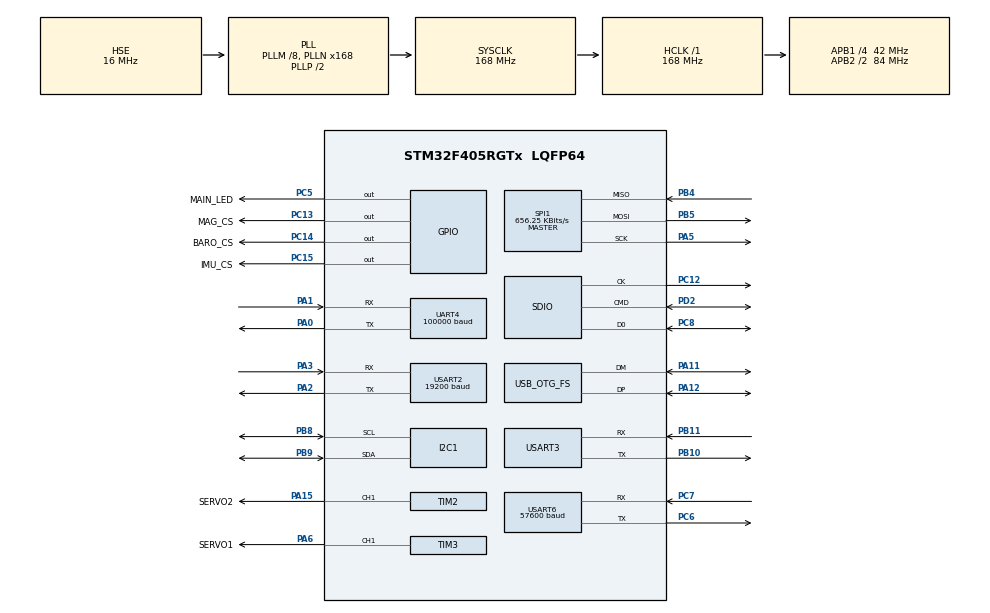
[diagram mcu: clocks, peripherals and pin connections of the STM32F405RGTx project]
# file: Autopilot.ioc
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Dma.Request0=SDIO_RX
Dma.Request1=SDIO_TX
Dma.Request2=USART3_RX
Dma.Request3=UART4_RX
Dma.Request4=USART6_RX
Dma.Request5=USART2_RX
Dma.SDIO_RX.0.Direction=DMA_PERIPH_TO_MEMORY
Dma.SDIO_RX.0.FIFOMode=DMA_FIFOMODE_ENABLE
Dma.SDIO_RX.0.FIFOThreshold=DMA_FIFO_THRESHOLD_FULL
Dma.SDIO_RX.0.Instance=DMA2_Stream3
Dma.SDIO_RX.0.MemBurst=DMA_MBURST_INC4
Dma.SDIO_RX.0.MemDataAlignment=DMA_MDATAALIGN_WORD
Dma.SDIO_RX.0.MemInc=DMA_MINC_ENABLE
Dma.SDIO_RX.0.Mode=DMA_PFCTRL
Dma.SDIO_RX.0.PeriphBurst=DMA_PBURST_INC4
Dma.SDIO_RX.0.PeriphDataAlignment=DMA_PDATAALIGN_WORD
Dma.SDIO_RX.0.PeriphInc=DMA_PINC_DISABLE
Dma.SDIO_RX.0.Priority=DMA_PRIORITY_LOW
Dma.SDIO_TX.1.Direction=DMA_MEMORY_TO_PERIPH
Dma.SDIO_TX.1.FIFOMode=DMA_FIFOMODE_ENABLE
Dma.SDIO_TX.1.FIFOThreshold=DMA_FIFO_THRESHOLD_FULL
Dma.SDIO_TX.1.Instance=DMA2_Stream6
Dma.SDIO_TX.1.MemBurst=DMA_MBURST_INC4
Dma.SDIO_TX.1.MemDataAlignment=DMA_MDATAALIGN_WORD
Dma.SDIO_TX.1.MemInc=DMA_MINC_ENABLE
Dma.SDIO_TX.1.Mode=DMA_PFCTRL
Dma.SDIO_TX.1.PeriphBurst=DMA_PBURST_INC4
Dma.SDIO_TX.1.PeriphDataAlignment=DMA_PDATAALIGN_WORD
Dma.SDIO_TX.1.PeriphInc=DMA_PINC_DISABLE
Dma.SDIO_TX.1.Priority=DMA_PRIORITY_LOW
Dma.UART4_RX.3.Direction=DMA_PERIPH_TO_MEMORY
Dma.UART4_RX.3.FIFOMode=DMA_FIFOMODE_DISABLE
Dma.UART4_RX.3.Instance=DMA1_Stream2
Dma.UART4_RX.3.MemDataAlignment=DMA_MDATAALIGN_BYTE
Dma.UART4_RX.3.MemInc=DMA_MINC_ENABLE
Dma.UART4_RX.3.Mode=DMA_NORMAL
Dma.UART4_RX.3.PeriphDataAlignment=DMA_PDATAALIGN_BYTE
Dma.UART4_RX.3.PeriphInc=DMA_PINC_DISABLE
Dma.UART4_RX.3.Priority=DMA_PRIORITY_LOW
Dma.USART2_RX.5.Direction=DMA_PERIPH_TO_MEMORY
Dma.USART2_RX.5.FIFOMode=DMA_FIFOMODE_DISABLE
Dma.USART2_RX.5.Instance=DMA1_Stream5
Dma.USART2_RX.5.MemDataAlignment=DMA_MDATAALIGN_BYTE
Dma.USART2_RX.5.MemInc=DMA_MINC_ENABLE
Dma.USART2_RX.5.Mode=DMA_NORMAL
Dma.USART2_RX.5.PeriphDataAlignment=DMA_PDATAALIGN_BYTE
Dma.USART2_RX.5.PeriphInc=DMA_PINC_DISABLE
Dma.USART2_RX.5.Priority=DMA_PRIORITY_LOW
Dma.USART3_RX.2.Direction=DMA_PERIPH_TO_MEMORY
Dma.USART3_RX.2.FIFOMode=DMA_FIFOMODE_DISABLE
Dma.USART3_RX.2.Instance=DMA1_Stream1
Dma.USART3_RX.2.MemDataAlignment=DMA_MDATAALIGN_BYTE
Dma.USART3_RX.2.MemInc=DMA_MINC_ENABLE
Dma.USART3_RX.2.Mode=DMA_NORMAL
Dma.USART3_RX.2.PeriphDataAlignment=DMA_PDATAALIGN_BYTE
Dma.USART3_RX.2.PeriphInc=DMA_PINC_DISABLE
Dma.USART3_RX.2.Priority=DMA_PRIORITY_LOW
Dma.USART6_RX.4.Direction=DMA_PERIPH_TO_MEMORY
Dma.USART6_RX.4.FIFOMode=DMA_FIFOMODE_DISABLE
Dma.USART6_RX.4.Instance=DMA2_Stream1
Dma.USART6_RX.4.MemDataAlignment=DMA_MDATAALIGN_BYTE
Dma.USART6_RX.4.MemInc=DMA_MINC_ENABLE
Dma.USART6_RX.4.Mode=DMA_NORMAL
Dma.USART6_RX.4.PeriphDataAlignment=DMA_PDATAALIGN_BYTE
Dma.USART6_RX.4.PeriphInc=DMA_PINC_DISABLE
Dma.USART6_RX.4.Priority=DMA_PRIORITY_LOW
FATFS.USE_DMA_CODE_SD=1
FATFS._MAX_SS=4096
FATFS._USE_LFN=1
I2C1.I2C_Mode=I2C_Fast
Mcu.Family=STM32F4
Mcu.Name=STM32F405RGTx
Mcu.Package=LQFP64
NVIC.DMA1_Stream1_IRQn=true\:0\:0\:false\:false\:true\:false\:true\:true
NVIC.DMA1_Stream2_IRQn=true\:0\:0\:false\:false\:true\:false\:true\:true
NVIC.DMA1_Stream5_IRQn=true\:0\:0\:false\:false\:true\:false\:true\:true
NVIC.DMA2_Stream1_IRQn=true\:0\:0\:false\:false\:true\:false\:true\:true
NVIC.DMA2_Stream3_IRQn=true\:0\:0\:false\:false\:true\:false\:true\:true
NVIC.DMA2_Stream6_IRQn=true\:0\:0\:false\:false\:true\:false\:true\:true
NVIC.OTG_FS_IRQn=true\:0\:0\:false\:false\:true\:false\:true\:true
NVIC.PriorityGroup=NVIC_PRIORITYGROUP_4
NVIC.SDIO_IRQn=true\:0\:0\:false\:false\:true\:true\:true\:true
NVIC.TIM6_DAC_IRQn=true\:15\:0\:true\:false\:true\:true\:true\:true
NVIC.TIM7_IRQn=true\:14\:0\:true\:false\:true\:true\:true\:true
PA0-WKUP.Mode=Asynchronous
PA0-WKUP.Signal=UART4_TX
PA1.Mode=Asynchronous
PA1.Signal=UART4_RX
PA11.Mode=Device_Only
PA11.Signal=USB_OTG_FS_DM
PA12.Mode=Device_Only
PA12.Signal=USB_OTG_FS_DP
PA13.Mode=Trace_Asynchronous_SW
PA13.Signal=SYS_JTMS-SWDIO
PA14.Mode=Trace_Asynchronous_SW
PA14.Signal=SYS_JTCK-SWCLK
PA15.GPIO_Label=SERVO2
PA15.Signal=S_TIM2_CH1_ETR
PA2.Mode=Asynchronous
PA2.Signal=USART2_TX
PA3.Mode=Asynchronous
PA3.Signal=USART2_RX
PA5.Mode=Full_Duplex_Master
PA5.Signal=SPI1_SCK
PA6.GPIO_Label=SERVO1
PA6.Signal=S_TIM3_CH1
PB10.Mode=Asynchronous
PB10.Signal=USART3_TX
PB11.Mode=Asynchronous
PB11.Signal=USART3_RX
PB3.Mode=Trace_Asynchronous_SW
PB3.Signal=SYS_JTDO-SWO
PB4.Mode=Full_Duplex_Master
PB4.Signal=SPI1_MISO
PB5.Mode=Full_Duplex_Master
PB5.Signal=SPI1_MOSI
PB8.Mode=I2C
PB8.Signal=I2C1_SCL
PB9.Mode=I2C
PB9.Signal=I2C1_SDA
PC12.Mode=SD_1_bit
PC12.Signal=SDIO_CK
PC13-ANTI_TAMP.GPIO_Label=MAG_CS
PC13-ANTI_TAMP.PinState=GPIO_PIN_SET
PC13-ANTI_TAMP.Signal=GPIO_Output
PC14-OSC32_IN.GPIO_Label=BARO_CS
PC14-OSC32_IN.PinState=GPIO_PIN_SET
PC14-OSC32_IN.Signal=GPIO_Output
PC15-OSC32_OUT.GPIO_Label=IMU_CS
PC15-OSC32_OUT.PinState=GPIO_PIN_SET
PC15-OSC32_OUT.Signal=GPIO_Output
PC5.GPIO_Label=MAIN_LED
PC5.Signal=GPIO_Output
PC6.Mode=Asynchronous
PC6.Signal=USART6_TX
PC7.Mode=Asynchronous
PC7.Signal=USART6_RX
PC8.Mode=SD_1_bit
PC8.Signal=SDIO_D0
PD2.Mode=SD_1_bit
PD2.Signal=SDIO_CMD
PH0-OSC_IN.Mode=HSE-External-Oscillator
PH0-OSC_IN.Signal=RCC_OSC_IN
PH1-OSC_OUT.Mode=HSE-External-Oscillator
PH1-OSC_OUT.Signal=RCC_OSC_OUT
ProjectManager.HeapSize=0x200
ProjectManager.StackSize=0x400
ProjectManager.TargetToolchain=STM32CubeIDE
RCC.48MHZClocksFreq_Value=48000000
RCC.AHBFreq_Value=168000000
RCC.APB1CLKDivider=RCC_HCLK_DIV4
RCC.APB1Freq_Value=42000000
RCC.APB1TimFreq_Value=84000000
RCC.APB2CLKDivider=RCC_HCLK_DIV2
RCC.APB2Freq_Value=84000000
RCC.APB2TimFreq_Value=168000000
RCC.CortexFreq_Value=168000000
RCC.HCLKFreq_Value=168000000
RCC.HSE_VALUE=16000000
RCC.HSI_VALUE=16000000
RCC.LSE_VALUE=32768
RCC.PLLM=8
RCC.PLLN=168
RCC.PLLQ=7
RCC.SYSCLKFreq_VALUE=168000000
RCC.SYSCLKSource=RCC_SYSCLKSOURCE_PLLCLK
RCC.VCOOutputFreq_Value=336000000
SH.S_TIM2_CH1_ETR.0=TIM2_CH1,PWM Generation1 CH1
SH.S_TIM3_CH1.0=TIM3_CH1,PWM Generation1 CH1
SPI1.BaudRatePrescaler=SPI_BAUDRATEPRESCALER_128
SPI1.CLKPhase=SPI_PHASE_2EDGE
SPI1.CLKPolarity=SPI_POLARITY_HIGH
SPI1.CalculateBaudRate=656.25 KBits/s
SPI1.Direction=SPI_DIRECTION_2LINES
SPI1.Mode=SPI_MODE_MASTER
SPI1.VirtualType=VM_MASTER
TIM2.Channel-PWM\ Generation1\ CH1=TIM_CHANNEL_1
TIM2.Period=1000-1
TIM2.Prescaler=1680-1
TIM3.Channel-PWM\ Generation1\ CH1=TIM_CHANNEL_1
TIM3.Period=1000-1
TIM3.Prescaler=1680-1
TIM5.Period=0xFFFFFFFF
TIM5.Prescaler=840-1
TIM6.Period=10000-1
TIM6.Prescaler=8400-1
TIM7.Period=100-1
TIM7.Prescaler=8400-1
UART4.BaudRate=100000
UART4.Parity=PARITY_EVEN
UART4.StopBits=UART_STOPBITS_2
UART4.VirtualMode=Asynchronous
USART2.BaudRate=19200
USART2.VirtualMode=VM_ASYNC
USART3.VirtualMode=VM_ASYNC
USART6.BaudRate=57600
USART6.VirtualMode=VM_ASYNC
USB_DEVICE.CLASS_NAME_FS=CDC
USB_DEVICE.VirtualMode-CDC_FS=Cdc
USB_DEVICE.VirtualModeFS=Cdc_FS
USB_OTG_FS.VirtualMode=Device_Only
VP_FATFS_VS_SDIO.Mode=SDIO
VP_TIM2_VS_ClockSourceINT.Mode=Internal
VP_TIM3_VS_ClockSourceINT.Mode=Internal
VP_TIM5_VS_ClockSourceINT.Mode=Internal
VP_TIM6_VS_ClockSourceINT.Mode=Enable_Timer
VP_TIM7_VS_ClockSourceINT.Mode=Enable_Timer
VP_USB_DEVICE_VS_USB_DEVICE_CDC_FS.Mode=CDC_FS
board=custom

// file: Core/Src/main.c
/* USER CODE BEGIN Header */
/**
  ******************************************************************************
  * @file           : main.c
  * @brief          : Main program body
  ******************************************************************************
  * @attention
  *
  * Copyright (c) 2024 STMicroelectronics.
  * All rights reserved.
  *
  * This software is licensed under terms that can be found in the LICENSE file
  * in the root directory of this software component.
  * If no LICENSE file comes with this software, it is provided AS-IS.
  *
  ******************************************************************************
  */
/* USER CODE END Header */
#include "main.h"
#include "fatfs.h"
#include "usb_device.h"

I2C_HandleTypeDef hi2c1;

SD_HandleTypeDef hsd;
DMA_HandleTypeDef hdma_sdio_rx;
DMA_HandleTypeDef hdma_sdio_tx;

SPI_HandleTypeDef hspi1;

TIM_HandleTypeDef htim2;
TIM_HandleTypeDef htim3;
TIM_HandleTypeDef htim5;
TIM_HandleTypeDef htim6;
TIM_HandleTypeDef htim7;

UART_HandleTypeDef huart4;
UART_HandleTypeDef huart2;
UART_HandleTypeDef huart3;
UART_HandleTypeDef huart6;
DMA_HandleTypeDef hdma_uart4_rx;
DMA_HandleTypeDef hdma_usart2_rx;
DMA_HandleTypeDef hdma_usart3_rx;
DMA_HandleTypeDef hdma_usart6_rx;

void SystemClock_Config(void);
static void MX_GPIO_Init(void);
static void MX_DMA_Init(void);
static void MX_SPI1_Init(void);
static void MX_SDIO_SD_Init(void);
static void MX_I2C1_Init(void);
static void MX_USART3_UART_Init(void);
static void MX_TIM7_Init(void);
static void MX_TIM5_Init(void);
static void MX_UART4_Init(void);
static void MX_USART6_UART_Init(void);
static void MX_TIM3_Init(void);
static void MX_TIM2_Init(void);
static void MX_USART2_UART_Init(void);
static void MX_TIM6_Init(void);

/* USER CODE BEGIN 0 */
int _write(int file, char* ptr, int len)
{
	for (int i = 0; i < len; i++)
	{
		ITM_SendChar(*ptr++);
	}

	return len;
}
/* USER CODE END 0 */

int main(void)
{

  /* MCU Configuration--------------------------------------------------------*/

  /* Reset of all peripherals, Initializes the Flash interface and the Systick. */
  HAL_Init();

  /* Configure the system clock */
  SystemClock_Config();

  /* Initialize all configured peripherals */
  MX_GPIO_Init();
  MX_DMA_Init();
  MX_SPI1_Init();
  MX_USB_DEVICE_Init();
  MX_SDIO_SD_Init();
  MX_I2C1_Init();
  MX_FATFS_Init();
  MX_USART3_UART_Init();
  MX_TIM7_Init();
  MX_TIM5_Init();
  MX_UART4_Init();
  MX_USART6_UART_Init();
  MX_TIM3_Init();
  MX_TIM2_Init();
  MX_USART2_UART_Init();
  MX_TIM6_Init();
  /* USER CODE BEGIN 2 */
  autopilot_main_c();
  /* USER CODE END 2 */

  /* Infinite loop */
  while (1)
  {

  }
}

void SystemClock_Config(void)
{
  RCC_OscInitTypeDef RCC_OscInitStruct = {0};
  RCC_ClkInitTypeDef RCC_ClkInitStruct = {0};

  /** Configure the main internal regulator output voltage
  */
  __HAL_RCC_PWR_CLK_ENABLE();
  __HAL_PWR_VOLTAGESCALING_CONFIG(PWR_REGULATOR_VOLTAGE_SCALE1);

  /** Initializes the RCC Oscillators according to the specified parameters
  * in the RCC_OscInitTypeDef structure.
  */
  RCC_OscInitStruct.OscillatorType = RCC_OSCILLATORTYPE_HSE;
  RCC_OscInitStruct.HSEState = RCC_HSE_ON;
  RCC_OscInitStruct.PLL.PLLState = RCC_PLL_ON;
  RCC_OscInitStruct.PLL.PLLSource = RCC_PLLSOURCE_HSE;
  RCC_OscInitStruct.PLL.PLLM = 8;
  RCC_OscInitStruct.PLL.PLLN = 168;
  RCC_OscInitStruct.PLL.PLLP = RCC_PLLP_DIV2;
  RCC_OscInitStruct.PLL.PLLQ = 7;
  if (HAL_RCC_OscConfig(&RCC_OscInitStruct) != HAL_OK)
  {
    Error_Handler();
  }

  /** Initializes the CPU, AHB and APB buses clocks
  */
  RCC_ClkInitStruct.ClockType = RCC_CLOCKTYPE_HCLK|RCC_CLOCKTYPE_SYSCLK
                              |RCC_CLOCKTYPE_PCLK1|RCC_CLOCKTYPE_PCLK2;
  RCC_ClkInitStruct.SYSCLKSource = RCC_SYSCLKSOURCE_PLLCLK;
  RCC_ClkInitStruct.AHBCLKDivider = RCC_SYSCLK_DIV1;
  RCC_ClkInitStruct.APB1CLKDivider = RCC_HCLK_DIV4;
  RCC_ClkInitStruct.APB2CLKDivider = RCC_HCLK_DIV2;

  if (HAL_RCC_ClockConfig(&RCC_ClkInitStruct, FLASH_LATENCY_5) != HAL_OK)
  {
    Error_Handler();
  }
}

static void MX_I2C1_Init(void)
{

  hi2c1.Instance = I2C1;
  hi2c1.Init.ClockSpeed = 400000;
  hi2c1.Init.DutyCycle = I2C_DUTYCYCLE_2;
  hi2c1.Init.OwnAddress1 = 0;
  hi2c1.Init.AddressingMode = I2C_ADDRESSINGMODE_7BIT;
  hi2c1.Init.DualAddressMode = I2C_DUALADDRESS_DISABLE;
  hi2c1.Init.OwnAddress2 = 0;
  hi2c1.Init.GeneralCallMode = I2C_GENERALCALL_DISABLE;
  hi2c1.Init.NoStretchMode = I2C_NOSTRETCH_DISABLE;
  if (HAL_I2C_Init(&hi2c1) != HAL_OK)
  {
    Error_Handler();
  }

}

static void MX_SDIO_SD_Init(void)
{

  hsd.Instance = SDIO;
  hsd.Init.ClockEdge = SDIO_CLOCK_EDGE_RISING;
  hsd.Init.ClockBypass = SDIO_CLOCK_BYPASS_DISABLE;
  hsd.Init.ClockPowerSave = SDIO_CLOCK_POWER_SAVE_DISABLE;
  hsd.Init.BusWide = SDIO_BUS_WIDE_1B;
  hsd.Init.HardwareFlowControl = SDIO_HARDWARE_FLOW_CONTROL_DISABLE;
  hsd.Init.ClockDiv = 0;

}

static void MX_SPI1_Init(void)
{

  /* SPI1 parameter configuration*/
  hspi1.Instance = SPI1;
  hspi1.Init.Mode = SPI_MODE_MASTER;
  hspi1.Init.Direction = SPI_DIRECTION_2LINES;
  hspi1.Init.DataSize = SPI_DATASIZE_8BIT;
  hspi1.Init.CLKPolarity = SPI_POLARITY_HIGH;
  hspi1.Init.CLKPhase = SPI_PHASE_2EDGE;
  hspi1.Init.NSS = SPI_NSS_SOFT;
  hspi1.Init.BaudRatePrescaler = SPI_BAUDRATEPRESCALER_128;
  hspi1.Init.FirstBit = SPI_FIRSTBIT_MSB;
  hspi1.Init.TIMode = SPI_TIMODE_DISABLE;
  hspi1.Init.CRCCalculation = SPI_CRCCALCULATION_DISABLE;
  hspi1.Init.CRCPolynomial = 10;
  if (HAL_SPI_Init(&hspi1) != HAL_OK)
  {
    Error_Handler();
  }

}

static void MX_TIM2_Init(void)
{

  TIM_ClockConfigTypeDef sClockSourceConfig = {0};
  TIM_MasterConfigTypeDef sMasterConfig = {0};
  TIM_OC_InitTypeDef sConfigOC = {0};

  htim2.Instance = TIM2;
  htim2.Init.Prescaler = 1680-1;
  htim2.Init.CounterMode = TIM_COUNTERMODE_UP;
  htim2.Init.Period = 1000-1;
  htim2.Init.ClockDivision = TIM_CLOCKDIVISION_DIV1;
  htim2.Init.AutoReloadPreload = TIM_AUTORELOAD_PRELOAD_DISABLE;
  if (HAL_TIM_Base_Init(&htim2) != HAL_OK)
  {
    Error_Handler();
  }
  sClockSourceConfig.ClockSource = TIM_CLOCKSOURCE_INTERNAL;
  if (HAL_TIM_ConfigClockSource(&htim2, &sClockSourceConfig) != HAL_OK)
  {
    Error_Handler();
  }
  if (HAL_TIM_PWM_Init(&htim2) != HAL_OK)
  {
    Error_Handler();
  }
  sMasterConfig.MasterOutputTrigger = TIM_TRGO_RESET;
  sMasterConfig.MasterSlaveMode = TIM_MASTERSLAVEMODE_DISABLE;
  if (HAL_TIMEx_MasterConfigSynchronization(&htim2, &sMasterConfig) != HAL_OK)
  {
    Error_Handler();
  }
  sConfigOC.OCMode = TIM_OCMODE_PWM1;
  sConfigOC.Pulse = 0;
  sConfigOC.OCPolarity = TIM_OCPOLARITY_HIGH;
  sConfigOC.OCFastMode = TIM_OCFAST_DISABLE;
  if (HAL_TIM_PWM_ConfigChannel(&htim2, &sConfigOC, TIM_CHANNEL_1) != HAL_OK)
  {
    Error_Handler();
  }
  HAL_TIM_MspPostInit(&htim2);

}

static void MX_TIM3_Init(void)
{

  TIM_ClockConfigTypeDef sClockSourceConfig = {0};
  TIM_MasterConfigTypeDef sMasterConfig = {0};
  TIM_OC_InitTypeDef sConfigOC = {0};

  htim3.Instance = TIM3;
  htim3.Init.Prescaler = 1680-1;
  htim3.Init.CounterMode = TIM_COUNTERMODE_UP;
  htim3.Init.Period = 1000-1;
  htim3.Init.ClockDivision = TIM_CLOCKDIVISION_DIV1;
  htim3.Init.AutoReloadPreload = TIM_AUTORELOAD_PRELOAD_DISABLE;
  if (HAL_TIM_Base_Init(&htim3) != HAL_OK)
  {
    Error_Handler();
  }
  sClockSourceConfig.ClockSource = TIM_CLOCKSOURCE_INTERNAL;
  if (HAL_TIM_ConfigClockSource(&htim3, &sClockSourceConfig) != HAL_OK)
  {
    Error_Handler();
  }
  if (HAL_TIM_PWM_Init(&htim3) != HAL_OK)
  {
    Error_Handler();
  }
  sMasterConfig.MasterOutputTrigger = TIM_TRGO_RESET;
  sMasterConfig.MasterSlaveMode = TIM_MASTERSLAVEMODE_DISABLE;
  if (HAL_TIMEx_MasterConfigSynchronization(&htim3, &sMasterConfig) != HAL_OK)
  {
    Error_Handler();
  }
  sConfigOC.OCMode = TIM_OCMODE_PWM1;
  sConfigOC.Pulse = 0;
  sConfigOC.OCPolarity = TIM_OCPOLARITY_HIGH;
  sConfigOC.OCFastMode = TIM_OCFAST_DISABLE;
  if (HAL_TIM_PWM_ConfigChannel(&htim3, &sConfigOC, TIM_CHANNEL_1) != HAL_OK)
  {
    Error_Handler();
  }
  HAL_TIM_MspPostInit(&htim3);

}

static void MX_TIM5_Init(void)
{

  TIM_ClockConfigTypeDef sClockSourceConfig = {0};
  TIM_MasterConfigTypeDef sMasterConfig = {0};

  htim5.Instance = TIM5;
  htim5.Init.Prescaler = 840-1;
  htim5.Init.CounterMode = TIM_COUNTERMODE_UP;
  htim5.Init.Period = 0xFFFFFFFF;
  htim5.Init.ClockDivision = TIM_CLOCKDIVISION_DIV1;
  htim5.Init.AutoReloadPreload = TIM_AUTORELOAD_PRELOAD_DISABLE;
  if (HAL_TIM_Base_Init(&htim5) != HAL_OK)
  {
    Error_Handler();
  }
  sClockSourceConfig.ClockSource = TIM_CLOCKSOURCE_INTERNAL;
  if (HAL_TIM_ConfigClockSource(&htim5, &sClockSourceConfig) != HAL_OK)
  {
    Error_Handler();
  }
  sMasterConfig.MasterOutputTrigger = TIM_TRGO_RESET;
  sMasterConfig.MasterSlaveMode = TIM_MASTERSLAVEMODE_DISABLE;
  if (HAL_TIMEx_MasterConfigSynchronization(&htim5, &sMasterConfig) != HAL_OK)
  {
    Error_Handler();
  }
  /* USER CODE BEGIN TIM5_Init 2 */
  if (HAL_TIM_Base_Start(&htim5) != HAL_OK)
  {
	  Error_Handler();
  }
  /* USER CODE END TIM5_Init 2 */

}

static void MX_TIM6_Init(void)
{

  TIM_MasterConfigTypeDef sMasterConfig = {0};

  htim6.Instance = TIM6;
  htim6.Init.Prescaler = 8400-1;
  htim6.Init.CounterMode = TIM_COUNTERMODE_UP;
  htim6.Init.Period = 10000-1;
  htim6.Init.AutoReloadPreload = TIM_AUTORELOAD_PRELOAD_DISABLE;
  if (HAL_TIM_Base_Init(&htim6) != HAL_OK)
  {
    Error_Handler();
  }
  sMasterConfig.MasterOutputTrigger = TIM_TRGO_RESET;
  sMasterConfig.MasterSlaveMode = TIM_MASTERSLAVEMODE_DISABLE;
  if (HAL_TIMEx_MasterConfigSynchronization(&htim6, &sMasterConfig) != HAL_OK)
  {
    Error_Handler();
  }

}

static void MX_TIM7_Init(void)
{

  TIM_MasterConfigTypeDef sMasterConfig = {0};

  htim7.Instance = TIM7;
  htim7.Init.Prescaler = 8400-1;
  htim7.Init.CounterMode = TIM_COUNTERMODE_UP;
  htim7.Init.Period = 100-1;
  htim7.Init.AutoReloadPreload = TIM_AUTORELOAD_PRELOAD_DISABLE;
  if (HAL_TIM_Base_Init(&htim7) != HAL_OK)
  {
    Error_Handler();
  }
  sMasterConfig.MasterOutputTrigger = TIM_TRGO_RESET;
  sMasterConfig.MasterSlaveMode = TIM_MASTERSLAVEMODE_DISABLE;
  if (HAL_TIMEx_MasterConfigSynchronization(&htim7, &sMasterConfig) != HAL_OK)
  {
    Error_Handler();
  }

}

static void MX_UART4_Init(void)
{

  huart4.Instance = UART4;
  huart4.Init.BaudRate = 100000;
  huart4.Init.WordLength = UART_WORDLENGTH_8B;
  huart4.Init.StopBits = UART_STOPBITS_2;
  huart4.Init.Parity = UART_PARITY_EVEN;
  huart4.Init.Mode = UART_MODE_TX_RX;
  huart4.Init.HwFlowCtl = UART_HWCONTROL_NONE;
  huart4.Init.OverSampling = UART_OVERSAMPLING_16;
  if (HAL_UART_Init(&huart4) != HAL_OK)
  {
    Error_Handler();
  }

}

static void MX_USART2_UART_Init(void)
{

  huart2.Instance = USART2;
  huart2.Init.BaudRate = 19200;
  huart2.Init.WordLength = UART_WORDLENGTH_8B;
  huart2.Init.StopBits = UART_STOPBITS_1;
  huart2.Init.Parity = UART_PARITY_NONE;
  huart2.Init.Mode = UART_MODE_TX_RX;
  huart2.Init.HwFlowCtl = UART_HWCONTROL_NONE;
  huart2.Init.OverSampling = UART_OVERSAMPLING_16;
  if (HAL_UART_Init(&huart2) != HAL_OK)
  {
    Error_Handler();
  }

}

static void MX_USART3_UART_Init(void)
{

  huart3.Instance = USART3;
  huart3.Init.BaudRate = 115200;
  huart3.Init.WordLength = UART_WORDLENGTH_8B;
  huart3.Init.StopBits = UART_STOPBITS_1;
  huart3.Init.Parity = UART_PARITY_NONE;
  huart3.Init.Mode = UART_MODE_TX_RX;
  huart3.Init.HwFlowCtl = UART_HWCONTROL_NONE;
  huart3.Init.OverSampling = UART_OVERSAMPLING_16;
  if (HAL_UART_Init(&huart3) != HAL_OK)
  {
    Error_Handler();
  }

}

static void MX_USART6_UART_Init(void)
{

  huart6.Instance = USART6;
  huart6.Init.BaudRate = 57600;
  huart6.Init.WordLength = UART_WORDLENGTH_8B;
  huart6.Init.StopBits = UART_STOPBITS_1;
  huart6.Init.Parity = UART_PARITY_NONE;
  huart6.Init.Mode = UART_MODE_TX_RX;
  huart6.Init.HwFlowCtl = UART_HWCONTROL_NONE;
  huart6.Init.OverSampling = UART_OVERSAMPLING_16;
  if (HAL_UART_Init(&huart6) != HAL_OK)
  {
    Error_Handler();
  }

}

static void MX_DMA_Init(void)
{

  /* DMA controller clock enable */
  __HAL_RCC_DMA2_CLK_ENABLE();
  __HAL_RCC_DMA1_CLK_ENABLE();

  /* DMA interrupt init */
  /* DMA1_Stream1_IRQn interrupt configuration */
  HAL_NVIC_SetPriority(DMA1_Stream1_IRQn, 0, 0);
  HAL_NVIC_EnableIRQ(DMA1_Stream1_IRQn);
  /* DMA1_Stream2_IRQn interrupt configuration */
  HAL_NVIC_SetPriority(DMA1_Stream2_IRQn, 0, 0);
  HAL_NVIC_EnableIRQ(DMA1_Stream2_IRQn);
  /* DMA1_Stream5_IRQn interrupt configuration */
  HAL_NVIC_SetPriority(DMA1_Stream5_IRQn, 0, 0);
  HAL_NVIC_EnableIRQ(DMA1_Stream5_IRQn);
  /* DMA2_Stream1_IRQn interrupt configuration */
  HAL_NVIC_SetPriority(DMA2_Stream1_IRQn, 0, 0);
  HAL_NVIC_EnableIRQ(DMA2_Stream1_IRQn);
  /* DMA2_Stream3_IRQn interrupt configuration */
  HAL_NVIC_SetPriority(DMA2_Stream3_IRQn, 0, 0);
  HAL_NVIC_EnableIRQ(DMA2_Stream3_IRQn);
  /* DMA2_Stream6_IRQn interrupt configuration */
  HAL_NVIC_SetPriority(DMA2_Stream6_IRQn, 0, 0);
  HAL_NVIC_EnableIRQ(DMA2_Stream6_IRQn);

}

static void MX_GPIO_Init(void)
{
  GPIO_InitTypeDef GPIO_InitStruct = {0};

  /* GPIO Ports Clock Enable */
  __HAL_RCC_GPIOC_CLK_ENABLE();
  __HAL_RCC_GPIOH_CLK_ENABLE();
  __HAL_RCC_GPIOA_CLK_ENABLE();
  __HAL_RCC_GPIOB_CLK_ENABLE();
  __HAL_RCC_GPIOD_CLK_ENABLE();

  /*Configure GPIO pin Output Level */
  HAL_GPIO_WritePin(GPIOC, MAG_CS_Pin|BARO_CS_Pin|IMU_CS_Pin, GPIO_PIN_SET);

  /*Configure GPIO pin Output Level */
  HAL_GPIO_WritePin(MAIN_LED_GPIO_Port, MAIN_LED_Pin, GPIO_PIN_RESET);

  /*Configure GPIO pins : MAG_CS_Pin BARO_CS_Pin IMU_CS_Pin MAIN_LED_Pin */
  GPIO_InitStruct.Pin = MAG_CS_Pin|BARO_CS_Pin|IMU_CS_Pin|MAIN_LED_Pin;
  GPIO_InitStruct.Mode = GPIO_MODE_OUTPUT_PP;
  GPIO_InitStruct.Pull = GPIO_NOPULL;
  GPIO_InitStruct.Speed = GPIO_SPEED_FREQ_LOW;
  HAL_GPIO_Init(GPIOC, &GPIO_InitStruct);

}

void Error_Handler(void)
{
  __disable_irq();
  while (1)
  {
  }
}
